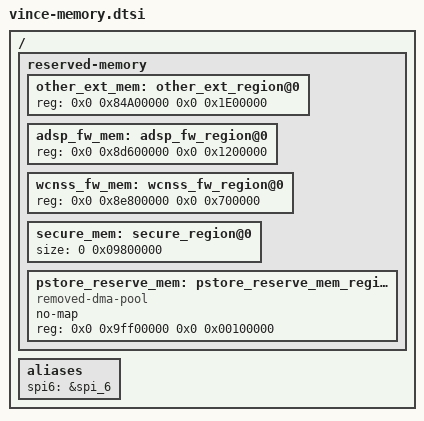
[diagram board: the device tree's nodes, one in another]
/*
 * Copyright (c) 2017, The Linux Foundation. All rights reserved.
 *
 * This program is free software; you can redistribute it and/or modify
 * it under the terms of the GNU General Public License version 2 and
 * only version 2 as published by the Free Software Foundation.
 *
 * This program is distributed in the hope that it will be useful,
 * but WITHOUT ANY WARRANTY; without even the implied warranty of
 * MERCHANTABILITY or FITNESS FOR A PARTICULAR PURPOSE.  See the
 * GNU General Public License for more details.
 */

/ {
	reserved-memory {
		other_ext_mem: other_ext_region@0 {
			reg = <0x0 0x84A00000 0x0 0x1E00000>;
		};
		adsp_fw_mem: adsp_fw_region@0 {
			reg = <0x0 0x8d600000 0x0 0x1200000>;
		};
		wcnss_fw_mem: wcnss_fw_region@0 {
			reg = <0x0 0x8e800000 0x0 0x700000>;
		};
		secure_mem: secure_region@0 {
			size = <0 0x09800000>;
		};
		pstore_reserve_mem: pstore_reserve_mem_region@0 {
			compatible = "removed-dma-pool";
			no-map;
			reg = <0x0 0x9ff00000 0x0 0x00100000>;
		};
	};
	aliases {
		spi6 = &spi_6;
	};
};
